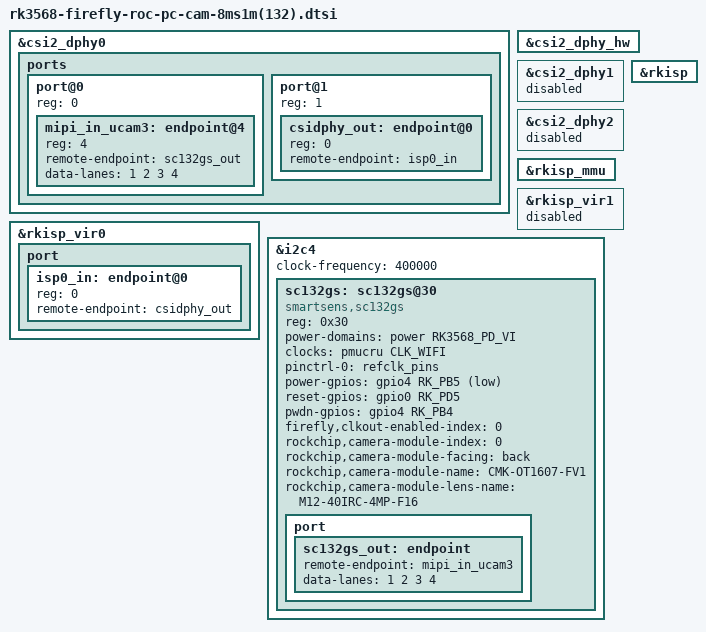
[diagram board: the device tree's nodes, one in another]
// SPDX-License-Identifier: (GPL-2.0+ OR MIT)
/*
 * Copyright (c) 2020 Rockchip Electronics Co., Ltd.
 *
 */

&csi2_dphy0 {
	status = "okay";

	ports {
		#address-cells = <1>;
		#size-cells = <0>;
		port@0 {
			reg = <0>;
			#address-cells = <1>;
			#size-cells = <0>;

			mipi_in_ucam3: endpoint@4 {
				reg = <4>;
				remote-endpoint = <&sc132gs_out>;
				data-lanes = <1 2 3 4>;
			};
		};
		port@1 {
			reg = <1>;
			#address-cells = <1>;
			#size-cells = <0>;

			csidphy_out: endpoint@0 {
				reg = <0>;
				remote-endpoint = <&isp0_in>;
			};
		};
	};
};
&csi2_dphy_hw {
   status = "okay";
};
&csi2_dphy1 {
	status = "disabled";
};

&csi2_dphy2 {
	status = "disabled";
};
&rkisp {
   status = "okay";
};

&rkisp_mmu {
   status = "okay";
};

&rkisp_vir0 {
	status = "okay";

	port {
		#address-cells = <1>;
		#size-cells = <0>;

		isp0_in: endpoint@0 {
			reg = <0>;
			remote-endpoint = <&csidphy_out>;
		};
	};
};

&rkisp_vir1 {
		status = "disabled";
};

&i2c4 {
	status = "okay";
	clock-frequency = <400000>;

	sc132gs: sc132gs@30{
        status = "okay";
        compatible = "smartsens,sc132gs";
        reg = <0x30>;

        clock-names = "xvclk";
        //avdd-supply = <&vcc_mipi>;
        power-domains = <&power RK3568_PD_VI>;
        pinctrl-names = "default";

		clocks = <&pmucru CLK_WIFI>;
        pinctrl-0 = <&refclk_pins>;

		//power-gpios = <&gpio0 RK_PB5 GPIO_ACTIVE_HIGH>;
        //reset-gpios = <&gpio0 RK_PD5 GPIO_ACTIVE_HIGH>;
		//pwdn-gpios = <&gpio4 RK_PB4 GPIO_ACTIVE_HIGH >;

		power-gpios = <&gpio4 RK_PB5 GPIO_ACTIVE_LOW>;
        reset-gpios = <&gpio0 RK_PD5 GPIO_ACTIVE_HIGH>;
        pwdn-gpios = <&gpio4 RK_PB4 GPIO_ACTIVE_HIGH>;

        firefly,clkout-enabled-index = <0>;
        rockchip,camera-module-index = <0>;
        rockchip,camera-module-facing = "back";
        //rockchip,camera-module-name = "NC";
        //rockchip,camera-module-lens-name = "NC";
		rockchip,camera-module-name = "CMK-OT1607-FV1";
        rockchip,camera-module-lens-name = "M12-40IRC-4MP-F16";
        port {
			sc132gs_out: endpoint {
				//xc7160b_out: endpoint {
				remote-endpoint = <&mipi_in_ucam3>;
                data-lanes = <1 2 3 4>;
            };
        };
    };
};
